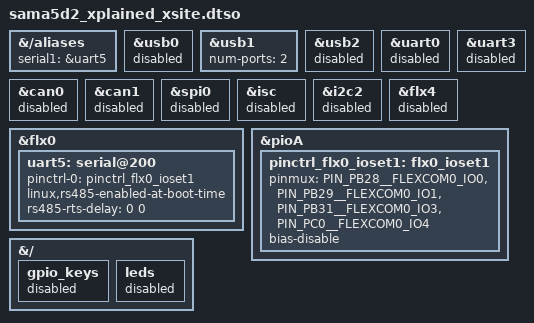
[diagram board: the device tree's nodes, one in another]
// SPDX-License-Identifier: (GPL-2.0+ OR MIT)
/*
 * sama5d2_xplained_flx0_i2c.dtso - Device Tree file for SAMA5D2 Xplained board
 * overlay blob to configure Flexcom0 as I2C.
 *
 * Copyright (C) 2020 Microchip Technology Inc. and its subsidiaries
 * Author: Codrin Ciubotariu <codrin.ciubotariu@microchip.com>
 *
 */
/dts-v1/;
/plugin/;

#include <dt-bindings/mfd/atmel-flexcom.h>
#include "sama5d2-pinfunc.h"
#include "dt-bindings/pinctrl/at91.h"

&{/aliases} {
    serial1 = &uart5; /* /dev/ttyS1 RS485 port */
};


&usb0 {
    status = "disabled";
};

&usb1 {
    num-ports = <2>;
};

&usb2 {
    status = "disabled";
};

&uart0 {
    status = "disabled";
};

&uart3 {
    status = "disabled";
};

&can0 {
    status = "disabled";
};

&can1 {
    status = "disabled";
};

&spi0 {
    status = "disabled";
};

&isc {
    status = "disabled";
};

&i2c2 {
   status = "disabled";
};


&flx0 {
    status = "okay"; /* conflict with ISC_D2 & ISC_D3 data pins */
    uart5: serial@200 {
        pinctrl-0 = <&pinctrl_flx0_ioset1>;
        linux,rs485-enabled-at-boot-time;
        rs485-rts-delay = <0 0>;
    };
};
&flx4 {
    status = "disabled";
};

&pioA {
    pinctrl_flx0_ioset1: flx0_ioset1 {
        pinmux = <PIN_PB28__FLEXCOM0_IO0>, /* TX */
                 <PIN_PB29__FLEXCOM0_IO1>, /* RX */
                 <PIN_PB31__FLEXCOM0_IO3>, /* CTS */
                 <PIN_PC0__FLEXCOM0_IO4>;  /* RTS */
        bias-disable;
    };
};

&{/} {
  gpio_keys {
    status = "disabled";
  };
};

&{/} {
  leds {
    status = "disabled";
  };
};
